# STM32F071xB register map
File version: 1.0
Registers are 32-bit, read-write, reset 0x0 unless marked. A register's access mark holds for its fields unless they carry their own. Offsets are from the block's base; [hi:lo] are bit positions; {n}, {i} and the like mark numbered series.

## CEC — HDMI-CEC
Base 0x40007800
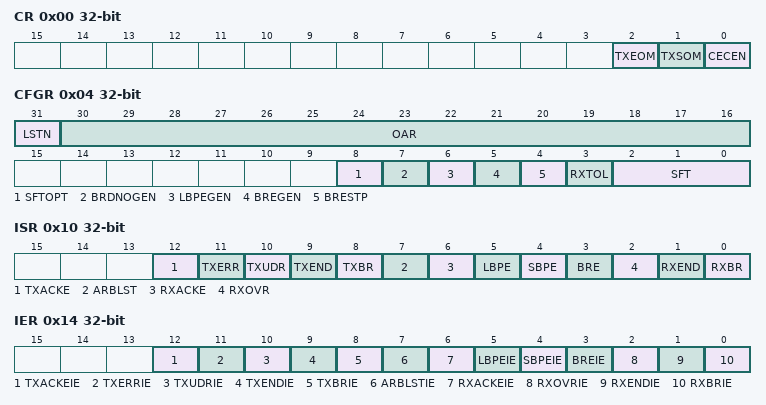
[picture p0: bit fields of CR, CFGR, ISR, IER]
0x00 CR — CEC control register
  [2] TXEOM — CEC Tx End Of Message
  [1] TXSOM — CEC Tx Start Of Message
  [0] CECEN — CEC Enable
0x04 CFGR — CEC configuration register
  [31] LSTN — CEC Listen mode
  [30:16] OAR — CEC Own Address
  [8] SFTOPT — CEC Signal Free Time optional
  [7] BRDNOGEN — CEC Broadcast No Error generation
  [6] LBPEGEN — CEC Long Bit Period Error gener
  [5] BREGEN — CEC Bit Rising Error generation
  [4] BRESTP — CEC Rx Stop
  [3] RXTOL — CEC Tolerance
  [2:0] SFT — CEC Signal Free Time
0x08 TXDR — CEC Tx data register
  [7:0] TXD — CEC Tx Data
0x0C RXDR — CEC Rx Data Register
  [7:0] RXD — CEC Rx Data
0x10 ISR — CEC Interrupt and Status Register
  [12] TXACKE — CEC Tx Missing Acknowledge
  [11] TXERR — CEC Tx-Error
  [10] TXUDR — CEC Tx-Buffer Underrun
  [9] TXEND — CEC End of Transmission
  [8] TXBR — CEC Tx Byte Request
  [7] ARBLST — CEC Arbitration Lost
  [6] RXACKE — CEC Rx Missing Acknowledge
  [5] LBPE — CEC Rx Long Bit period Error
  [4] SBPE — CEC Rx Short Bit period Error
  [3] BRE — CEC Rx Bit Rising Error
  [2] RXOVR — CEC Rx-Overrun
  [1] RXEND — CEC End Of Reception
  [0] RXBR — CEC Rx-Byte Received
0x14 IER — CEC interrupt enable register
  [12] TXACKEIE — CEC Tx Missing Acknowledge IT Enable
  [11] TXERRIE — CEC Tx-Error IT Enable
  [10] TXUDRIE — CEC Tx-Buffer Underrun IT Enable
  [9] TXENDIE — CEC End of Transmission IT Enable
  [8] TXBRIE — CEC Tx Byte Request IT Enable
  [7] ARBLSTIE — CEC Arbitration Lost IT Enable
  [6] RXACKEIE — CEC Rx Missing Acknowledge IT Enable
  [5] LBPEIE — CEC Rx Long Bit period Error IT Enable
  [4] SBPEIE — CEC Rx Short Bit period Error IT Enable
  [3] BREIE — CEC Rx Bit Rising Error IT Enable
  [2] RXOVRIE — CEC Rx-Overrun IT Enable
  [1] RXENDIE — CEC End Of Reception IT Enable
  [0] RXBRIE — CEC Rx-Byte Received IT Enable

## SYSCFG — SysTem Configuration
Base 0x40010000
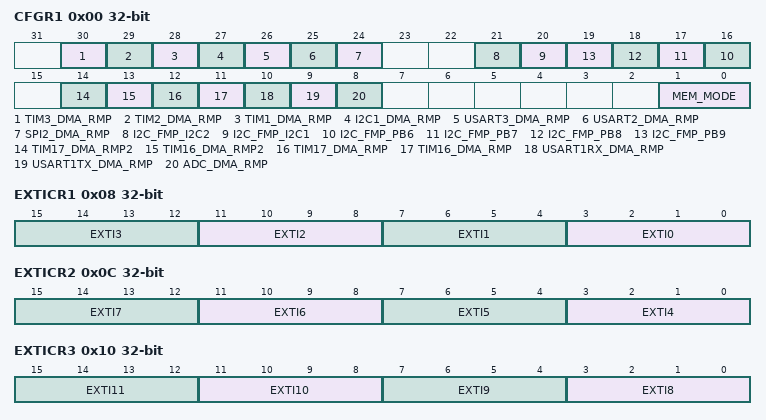
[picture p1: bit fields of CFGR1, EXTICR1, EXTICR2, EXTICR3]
0x00 CFGR1 — SYSCFG configuration register 1
  [30] TIM3_DMA_RMP — TIM3 DMA remap
  [29] TIM2_DMA_RMP — TIM2 DMA remap
  [28] TIM1_DMA_RMP — TIM1 DMA remap
  [27] I2C1_DMA_RMP — I2C1 DMA remap
    0=CH32 (I2C1_RX and I2C1_TX DMA requests mapped on DMA channel 3U and 2U respectively); 1=CH76 (I2C1_RX and I2C1_TX DMA requests mapped on DMA channel 7 and 6 respectively)
  [26] USART3_DMA_RMP — USART3 DMA remap
  [25] USART2_DMA_RMP — USART2 DMA remap
  [24] SPI2_DMA_RMP — SPI2 DMA remap
    0=CH45 (SPI2_RX and SPI2_TX DMA requests mapped on DMA channel 4U and 5 respectively); 1=CH67 (SPI2_RX and SPI2_TX DMA requests mapped on DMA channel 6 and 7 respectively)
  [21] I2C_FMP_I2C2 — Enable I2C2 Fast mode plus
  [20] I2C_FMP_I2C1 — Enable Fast Mode Plus on PB10, PB11, PF6 and PF7
  [n+10] I2C_FMP_PB{n} (n=6..9) — I2C PB{n} Fast mode plus
  [14] TIM17_DMA_RMP2 — Timer 17 DMA remap 2
  [13] TIM16_DMA_RMP2 — Timer 16 DMA remap 2
  [12] TIM17_DMA_RMP — Timer 17 DMA remap
  [11] TIM16_DMA_RMP — Timer 16 DMA remap
  [10] USART1RX_DMA_RMP — USART1 RX DMA remap
  [9] USART1TX_DMA_RMP — USART1 TX DMA remap
  [8] ADC_DMA_RMP — ADC DMA remap
    0=CH1 (ADC DMA request mapped on DMA channel 1U); 1=CH2 (ADC DMA request mapped on DMA channel 2U)
  [1:0] MEM_MODE — SYSCFG_Memory Remap Config
    0=FLASH (Main Flash memory mapped at 0x00000000); 1=SYSTEMFLASH (System Flash memory mapped at 0x00000000); 3=SRAM (Embedded SRAM mapped at 0x00000000)
0x08 EXTICR1 — SYSCFG external interrupt configuration register
  [4n+3:4n] EXTI{n} (n=0..3) — EXTI {n} configuration
0x0C EXTICR2 — SYSCFG external interrupt configuration register
  [4n-13:4n-16] EXTI{n} (n=4..7) — EXTI {n} configuration
0x10 EXTICR3 — SYSCFG external interrupt configuration register
  [4n-29:4n-32] EXTI{n} (n=8..11) — EXTI {n} configuration
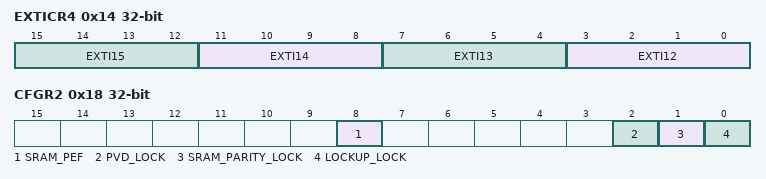
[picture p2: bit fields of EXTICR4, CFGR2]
0x14 EXTICR4 — SYSCFG external interrupt configuration register
  [4n-45:4n-48] EXTI{n} (n=12..15) — EXTI {n} configuration
0x18 CFGR2 — SYSCFG configuration register 2
  [8] SRAM_PEF — SRAM Parity error flag
  [2] PVD_LOCK — Enables and locks the PVD connection with Timer1 Break Input and also the PVD_EN and PVDSEL[2:0] bits of the Power Control Interface
  [1] SRAM_PARITY_LOCK — Enables and locks the SRAM_PARITY error signal with Break Input of TIMER1
  [0] LOCKUP_LOCK — Enables and locks the LOCKUP (Hardfault) output of CortexM0 with Break Input of TIMER1
